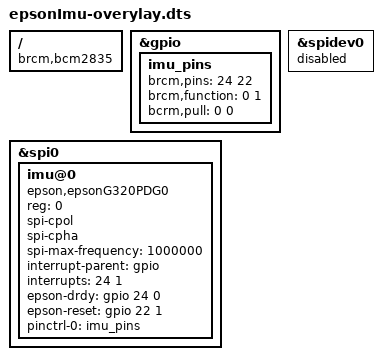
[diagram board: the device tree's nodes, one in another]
/*
* epsonImu-overlay.dts
*
* EpsonImu (inertial measurement unit) connected to spi0 on Raspberry Pi
*
*/
/dts-v1/;
/plugin/;

/ {

        compatible = "brcm,bcm2835";
        /* the interrupt pin of the Imu device */
        fragment@0 {
                target = <&gpio>;
                __overlay__ {
                imu_pins: imu_pins {
                                brcm,pins = <24 22>;
                                brcm,function = <0 1>; /* input output */
                                bcrm,pull = <0 0>; /* disable pull-up */
                        };
                };
        };

        /* disable spi-dev for spi0.0 */
        fragment@1 {
                target = <&spi0>;
                __overlay__ {
                        status = "okay";
                };
        };

        fragment@2 {
                target = <&spidev0>;
                __overlay__ {
                        status = "disabled";
                };
        };

        fragment@3 {
                target = <&spi0>;
                __overlay__ {
                        /* needed to avoid dtc warning */
                        #address-cells = <1>;
                        #size-cells = <0>;
                        imu@0 {
                                reg = <0>;
                                compatible = "epson,epsonG320PDG0";
                                spi-cpol;
                                spi-cpha;
                                spi-max-frequency = <1000000>;
                                interrupt-parent = <&gpio>;
                                interrupts = <24 1>;/* IRQ_TYPE_EDGE_RISING */
                                epson-drdy = <&gpio 24 0>;
                                epson-reset = <&gpio 22 1>;
                                /* epson-proto; */
                                pinctrl-names = "default";
                                pinctrl-0 = <&imu_pins>;
                        };
                };
        };
};

